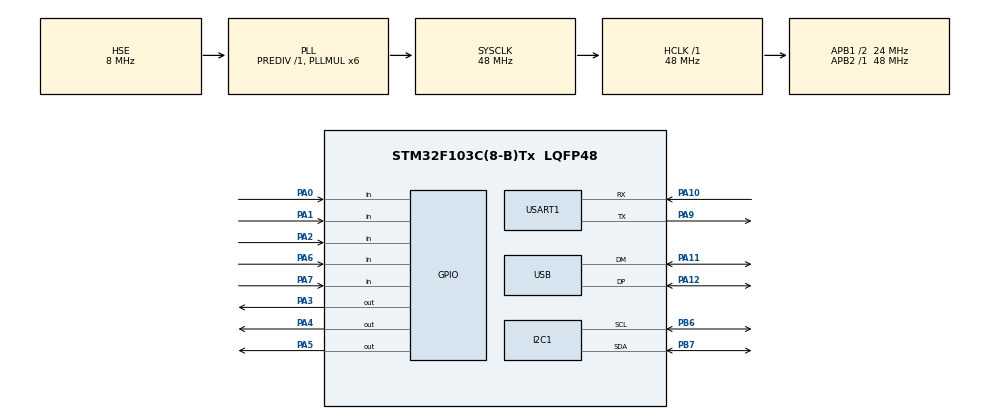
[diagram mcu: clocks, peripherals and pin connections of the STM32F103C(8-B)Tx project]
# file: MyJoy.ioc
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Mcu.Family=STM32F1
Mcu.Name=STM32F103C(8-B)Tx
Mcu.Package=LQFP48
NVIC.PriorityGroup=NVIC_PRIORITYGROUP_4
NVIC.USB_LP_CAN1_RX0_IRQn=true\:0\:0\:false\:false\:true
PA0-WKUP.GPIO_PuPd=GPIO_PULLUP
PA0-WKUP.Signal=GPIO_Input
PA1.GPIO_PuPd=GPIO_PULLUP
PA1.Signal=GPIO_Input
PA10.Mode=Asynchronous
PA10.Signal=USART1_RX
PA11.Mode=Device
PA11.Signal=USB_DM
PA12.Mode=Device
PA12.Signal=USB_DP
PA13.Mode=Serial_Wire
PA13.Signal=SYS_JTMS-SWDIO
PA14.Mode=Serial_Wire
PA14.Signal=SYS_JTCK-SWCLK
PA2.GPIO_PuPd=GPIO_PULLUP
PA2.Signal=GPIO_Input
PA3.GPIO_Speed=GPIO_SPEED_FREQ_LOW
PA3.Signal=GPIO_Output
PA4.Signal=GPIO_Output
PA5.Signal=GPIO_Output
PA6.GPIO_PuPd=GPIO_PULLUP
PA6.Signal=GPIO_Input
PA7.GPIO_PuPd=GPIO_PULLUP
PA7.Signal=GPIO_Input
PA9.Mode=Asynchronous
PA9.Signal=USART1_TX
PB6.Mode=I2C
PB6.Signal=I2C1_SCL
PB7.Mode=I2C
PB7.Signal=I2C1_SDA
PD0-OSC_IN.Mode=HSE-External-Oscillator
PD0-OSC_IN.Signal=RCC_OSC_IN
PD1-OSC_OUT.Mode=HSE-External-Oscillator
PD1-OSC_OUT.Signal=RCC_OSC_OUT
ProjectManager.HeapSize=0x200
ProjectManager.StackSize=0x400
ProjectManager.TargetToolchain=Other Toolchains (GPDSC)
RCC.ADCPresc=RCC_ADCPCLK2_DIV4
RCC.AHBFreq_Value=48000000
RCC.APB1CLKDivider=RCC_HCLK_DIV2
RCC.APB1Freq_Value=24000000
RCC.APB1TimFreq_Value=48000000
RCC.APB2Freq_Value=48000000
RCC.APB2TimFreq_Value=48000000
RCC.HCLKFreq_Value=48000000
RCC.HSIState=RCC_HSI_ON
RCC.PLLMUL=RCC_PLL_MUL6
RCC.PLLSourceVirtual=RCC_PLLSOURCE_HSE
RCC.SYSCLKFreq_VALUE=48000000
RCC.SYSCLKSource=RCC_SYSCLKSOURCE_PLLCLK
RCC.USBFreq_Value=48000000
USB_DEVICE.USBD_CUSTOMHID_OUTREPORT_BUF_SIZE=8
USB_DEVICE.USBD_CUSTOM_HID_REPORT_DESC_SIZE=87
USB_DEVICE.USBD_DEBUG_LEVEL=0
USB_DEVICE.USBD_HandleTypeDef=hUsbDeviceFS
USB_DEVICE.USBD_SUPPORT_USER_STRING=1
USB_DEVICE.VirtualMode=CustomHid
USB_DEVICE.VirtualModeFS=Custom_Hid_FS
VP_USB_DEVICE_VS_USB_DEVICE_CUSTOM_HID_FS.Mode=CUSTOM_HID_FS
board=MyJoy

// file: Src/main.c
/**
  ******************************************************************************
  * File Name          : main.c
  * Description        : Main program body
  ******************************************************************************
  *
  * Copyright (c) 2016 STMicroelectronics International N.V.
  * All rights reserved.
  *
  * Redistribution and use in source and binary forms, with or without
  * modification, are permitted, provided that the following conditions are met:
  *
  * 1. Redistribution of source code must retain the above copyright notice,
  *    this list of conditions and the following disclaimer.
  * 2. Redistributions in binary form must reproduce the above copyright notice,
  *    this list of conditions and the following disclaimer in the documentation
  *    and/or other materials provided with the distribution.
  * 3. Neither the name of STMicroelectronics nor the names of other
  *    contributors to this software may be used to endorse or promote products
  *    derived from this software without specific written permission.
  * 4. This software, including modifications and/or derivative works of this
  *    software, must execute solely and exclusively on microcontroller or
  *    microprocessor devices manufactured by or for STMicroelectronics.
  * 5. Redistribution and use of this software other than as permitted under
  *    this license is void and will automatically terminate your rights under
  *    this license.
  *
  * THIS SOFTWARE IS PROVIDED BY STMICROELECTRONICS AND CONTRIBUTORS "AS IS"
  * AND ANY EXPRESS, IMPLIED OR STATUTORY WARRANTIES, INCLUDING, BUT NOT
  * LIMITED TO, THE IMPLIED WARRANTIES OF MERCHANTABILITY, FITNESS FOR A
  * PARTICULAR PURPOSE AND NON-INFRINGEMENT OF THIRD PARTY INTELLECTUAL PROPERTY
  * RIGHTS ARE DISCLAIMED TO THE FULLEST EXTENT PERMITTED BY LAW. IN NO EVENT
  * SHALL STMICROELECTRONICS OR CONTRIBUTORS BE LIABLE FOR ANY DIRECT, INDIRECT,
  * INCIDENTAL, SPECIAL, EXEMPLARY, OR CONSEQUENTIAL DAMAGES (INCLUDING, BUT NOT
  * LIMITED TO, PROCUREMENT OF SUBSTITUTE GOODS OR SERVICES; LOSS OF USE, DATA,
  * OR PROFITS; OR BUSINESS INTERRUPTION) HOWEVER CAUSED AND ON ANY THEORY OF
  * LIABILITY, WHETHER IN CONTRACT, STRICT LIABILITY, OR TORT (INCLUDING
  * NEGLIGENCE OR OTHERWISE) ARISING IN ANY WAY OUT OF THE USE OF THIS SOFTWARE,
  * EVEN IF ADVISED OF THE POSSIBILITY OF SUCH DAMAGE.
  *
  ******************************************************************************
  */
#include "main.h"
#include "stm32f1xx_hal.h"
#include "usb_device.h"

/* USER CODE BEGIN Includes */
#include "usbd_customhid.h"
/* USER CODE END Includes */

I2C_HandleTypeDef hi2c1;

UART_HandleTypeDef huart1;

/* USER CODE BEGIN PV */
extern USBD_HandleTypeDef hUsbDeviceFS;
USBD_CUSTOM_HID_ItfTypeDef  USBD_CustomHID_fops_FS;

/* Private variables ---------------------------------------------------------*/
/* USER CODE END PV */

void SystemClock_Config(void);
void Error_Handler(void);
static void MX_GPIO_Init(void);
static void MX_USART1_UART_Init(void);
static void MX_I2C1_Init(void);

/* USER CODE BEGIN PFP */
void RHIDCheckState();
/* Private function prototypes -----------------------------------------------*/

/* USER CODE END PFP */

int main(void)
{

  /* MCU Configuration----------------------------------------------------------*/

  /* Reset of all peripherals, Initializes the Flash interface and the Systick. */
  HAL_Init();

  /* Configure the system clock */
  SystemClock_Config();

  /* Initialize all configured peripherals */
  MX_GPIO_Init();
  MX_USART1_UART_Init();
  MX_I2C1_Init();
  MX_USB_DEVICE_Init();

  /* USER CODE BEGIN 2 */

	init();

  /* USER CODE END 2 */

  /* Infinite loop */
  /* USER CODE BEGIN WHILE */

// simply draw circles
//	struct joystick_report_t report = {
//		0,
//		0,
//		0,
//		0,
//		0
//	};
//	int v = 0;
//	double radius = 32767;
//	double angle = 0;
//	while (1)
//	{
//		//HAL_Delay(10);
//		double x = cos(angle * 3.14 / 180.0)*radius;  // value -127 .. 128
//		double y = sin(angle * 3.14 / 180.0)*radius;  // value -127 .. 128
//		double z = cos(angle * 3.14 / 180.0)*radius;  // value -127 .. 128
//		double t = cos(angle * 3.14 / 180.0)*radius;  // value -127 .. 128
//		angle += 0.1;
//		report.x = x;
//		report.y = y;
//		report.z = z;
//		report.throttle = t;
//		USBD_CUSTOM_HID_SendReport(&hUsbDeviceFS, (uint8_t*)&report, sizeof(report));
//	}

	while (1)
	{

		//HAL_Delay(100);

		//if (bDeviceState == CONFIGURED)
		{
			if (PrevXferComplete)
			{

				RHIDCheckState();
			}
		}

  /* USER CODE END WHILE */

	}

}

/** System Clock Configuration
*/
void SystemClock_Config(void)
{

  RCC_OscInitTypeDef RCC_OscInitStruct;
  RCC_ClkInitTypeDef RCC_ClkInitStruct;
  RCC_PeriphCLKInitTypeDef PeriphClkInit;

    /**Initializes the CPU, AHB and APB busses clocks
    */
  RCC_OscInitStruct.OscillatorType = RCC_OSCILLATORTYPE_HSE;
  RCC_OscInitStruct.HSEState = RCC_HSE_ON;
  RCC_OscInitStruct.HSEPredivValue = RCC_HSE_PREDIV_DIV1;
  RCC_OscInitStruct.HSIState = RCC_HSI_ON;
  RCC_OscInitStruct.PLL.PLLState = RCC_PLL_ON;
  RCC_OscInitStruct.PLL.PLLSource = RCC_PLLSOURCE_HSE;
  RCC_OscInitStruct.PLL.PLLMUL = RCC_PLL_MUL6;
  if (HAL_RCC_OscConfig(&RCC_OscInitStruct) != HAL_OK)
  {
    Error_Handler();
  }

    /**Initializes the CPU, AHB and APB busses clocks
    */
  RCC_ClkInitStruct.ClockType = RCC_CLOCKTYPE_HCLK|RCC_CLOCKTYPE_SYSCLK
                              |RCC_CLOCKTYPE_PCLK1|RCC_CLOCKTYPE_PCLK2;
  RCC_ClkInitStruct.SYSCLKSource = RCC_SYSCLKSOURCE_PLLCLK;
  RCC_ClkInitStruct.AHBCLKDivider = RCC_SYSCLK_DIV1;
  RCC_ClkInitStruct.APB1CLKDivider = RCC_HCLK_DIV2;
  RCC_ClkInitStruct.APB2CLKDivider = RCC_HCLK_DIV1;

  if (HAL_RCC_ClockConfig(&RCC_ClkInitStruct, FLASH_LATENCY_1) != HAL_OK)
  {
    Error_Handler();
  }

  PeriphClkInit.PeriphClockSelection = RCC_PERIPHCLK_USB;
  PeriphClkInit.UsbClockSelection = RCC_USBCLKSOURCE_PLL;
  if (HAL_RCCEx_PeriphCLKConfig(&PeriphClkInit) != HAL_OK)
  {
    Error_Handler();
  }

    /**Configure the Systick interrupt time
    */
  HAL_SYSTICK_Config(HAL_RCC_GetHCLKFreq()/1000);

    /**Configure the Systick
    */
  HAL_SYSTICK_CLKSourceConfig(SYSTICK_CLKSOURCE_HCLK);

  /* SysTick_IRQn interrupt configuration */
  HAL_NVIC_SetPriority(SysTick_IRQn, 0, 0);
}

/* I2C1 init function */
static void MX_I2C1_Init(void)
{

  hi2c1.Instance = I2C1;
  hi2c1.Init.ClockSpeed = 100000;
  hi2c1.Init.DutyCycle = I2C_DUTYCYCLE_2;
  hi2c1.Init.OwnAddress1 = 0;
  hi2c1.Init.AddressingMode = I2C_ADDRESSINGMODE_7BIT;
  hi2c1.Init.DualAddressMode = I2C_DUALADDRESS_DISABLE;
  hi2c1.Init.OwnAddress2 = 0;
  hi2c1.Init.GeneralCallMode = I2C_GENERALCALL_DISABLE;
  hi2c1.Init.NoStretchMode = I2C_NOSTRETCH_DISABLE;
  if (HAL_I2C_Init(&hi2c1) != HAL_OK)
  {
    Error_Handler();
  }

}

/* USART1 init function */
static void MX_USART1_UART_Init(void)
{

  huart1.Instance = USART1;
  huart1.Init.BaudRate = 115200;
  huart1.Init.WordLength = UART_WORDLENGTH_8B;
  huart1.Init.StopBits = UART_STOPBITS_1;
  huart1.Init.Parity = UART_PARITY_NONE;
  huart1.Init.Mode = UART_MODE_TX_RX;
  huart1.Init.HwFlowCtl = UART_HWCONTROL_NONE;
  huart1.Init.OverSampling = UART_OVERSAMPLING_16;
  if (HAL_UART_Init(&huart1) != HAL_OK)
  {
    Error_Handler();
  }

}

/** Configure pins as
        * Analog
        * Input
        * Output
        * EVENT_OUT
        * EXTI
*/
static void MX_GPIO_Init(void)
{

  GPIO_InitTypeDef GPIO_InitStruct;

  /* GPIO Ports Clock Enable */
  __HAL_RCC_GPIOD_CLK_ENABLE();
  __HAL_RCC_GPIOA_CLK_ENABLE();
  __HAL_RCC_GPIOB_CLK_ENABLE();

  /*Configure GPIO pins : PA0 PA1 PA2 PA6
                           PA7 */
  GPIO_InitStruct.Pin = GPIO_PIN_0|GPIO_PIN_1|GPIO_PIN_2|GPIO_PIN_6
                          |GPIO_PIN_7;
  GPIO_InitStruct.Mode = GPIO_MODE_INPUT;
  GPIO_InitStruct.Pull = GPIO_PULLUP;
  HAL_GPIO_Init(GPIOA, &GPIO_InitStruct);

  /*Configure GPIO pins : PA3 PA4 PA5 */
  GPIO_InitStruct.Pin = GPIO_PIN_3|GPIO_PIN_4|GPIO_PIN_5;
  GPIO_InitStruct.Mode = GPIO_MODE_OUTPUT_PP;
  GPIO_InitStruct.Speed = GPIO_SPEED_FREQ_LOW;
  HAL_GPIO_Init(GPIOA, &GPIO_InitStruct);

  /*Configure GPIO pin Output Level */
  HAL_GPIO_WritePin(GPIOA, GPIO_PIN_3|GPIO_PIN_4|GPIO_PIN_5, GPIO_PIN_RESET);

}

void Error_Handler(void)
{
  /* USER CODE BEGIN Error_Handler */
	printf("!!! FATAL ERROR !!!");
  /* User can add his own implementation to report the HAL error return state */
	while (1)
	{
	}
  /* USER CODE END Error_Handler */
}

/************************ (C) COPYRIGHT STMicroelectronics *****END OF FILE****/
